# ATtiny828 register map
Vendor: Atmel; File version: 1.0
CPU: other r0p0, little endian, no MPU, no FPU, 4 interrupt priority bits
Registers are 8-bit, read-write, reset 0x0 unless marked. A register's access mark holds for its fields unless they carry their own. Offsets are from the block's base; [hi:lo] are bit positions; {n}, {i} and the like mark numbered series.

## LOCKBIT — Lockbits
Base 0x00000000
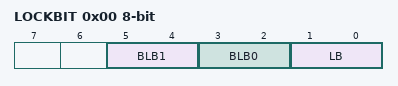
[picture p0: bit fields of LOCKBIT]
0x00 LOCKBIT
  [5:4] BLB1 — Boot Loader Protection Mode
    0=LPM_SPM_DISABLE (LPM and SPM prohibited in Boot Section); 1=LPM_DISABLE (LPM prohibited in Boot Section); 2=SPM_DISABLE (SPM prohibited in Boot Section); 3=NO_LOCK (No lock on SPM and LPM in Boot Section)
  [3:2] BLB0 — Boot Loader Protection Mode
    0=LPM_SPM_DISABLE (LPM and SPM prohibited in Application Section); 1=LPM_DISABLE (LPM prohibited in Application Section); 2=SPM_DISABLE (SPM prohibited in Application Section); 3=NO_LOCK (No lock on SPM and LPM in Application Section)
  [1:0] LB — Memory Lock
    0=PROG_VER_DISABLED (Further programming and verification disabled); 2=PROG_DISABLED (Further programming disabled); 3=NO_LOCK (No memory lock features enabled)

## PORTA — I/O Port
Base 0x00000020
0x00 PINA — Port A Input Pins
0x01 DDRA — Data Direction Register, Port A
0x02 PORTA — Port A Data Register
0x03 PUEA — Pull-up Enable Control Register

## PORTB — I/O Port
Base 0x00000024
0x00 PINB — Port B Input Pins
0x01 DDRB — Data Direction Register, Port B
0x02 PORTB — Port B Data Register
0x03 PUEB — Pull-up Enable Control Register

## PORTC — I/O Port
Base 0x00000028
0x00 PINC — Port C Input Pins
0x01 DDRC — Data Direction Register, Port C
0x02 PORTC — Port C Data Register
0x03 PUEC — Pull-up Enable Control Register
0x0C PHDE — Port High Drive Enable Register
  [2] PHDEC — Port C High Drive Enable

## PORTD — I/O Port
Base 0x0000002C
0x00 PIND — Port D Input Pins
0x01 DDRD — Data Direction Register, Port D
0x02 PORTD — Port D Data Register
0x03 PUED — Pull-up Enable Control Register

## SPI — Serial Peripheral Interface
Base 0x0000004C
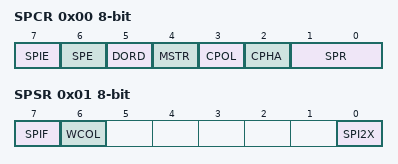
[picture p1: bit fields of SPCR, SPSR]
0x00 SPCR — SPI Control Register
  [7] SPIE — SPI Interrupt Enable
  [6] SPE — SPI Enable
  [5] DORD — Data Order
  [4] MSTR — Master/Slave Select
  [3] CPOL — Clock polarity
  [2] CPHA — Clock Phase
  [1:0] SPR — SPI Clock Rate Selects
    0=FOSC_4; 1=FOSC_16; 3=FOSC_128
0x01 SPSR — SPI Status Register
  [7] SPIF — SPI Interrupt Flag
  [6] WCOL — Write Collision Flag
  [0] SPI2X — Double SPI Speed Bit
0x02 SPDR — SPI Data Register

## TC0 — Timer/Counter, 8-bit
Base 0x00000035
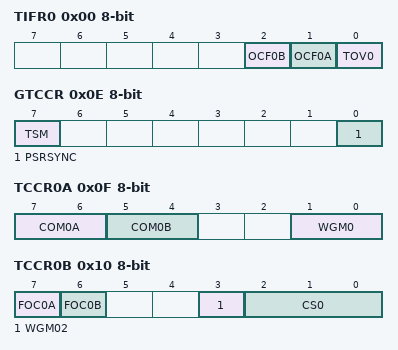
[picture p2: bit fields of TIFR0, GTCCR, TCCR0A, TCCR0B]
0x00 TIFR0 — Timer/Counter0 Interrupt Flag register
  [2] OCF0B — Timer/Counter0 Output Compare Flag 0B
  [1] OCF0A — Timer/Counter0 Output Compare Flag 0A
  [0] TOV0 — Timer/Counter0 Overflow Flag
0x0E GTCCR — General Timer/Counter Control Register
  [7] TSM — Timer/Counter Synchronization Mode
  [0] PSRSYNC — Prescaler Reset Timer/Counter1 and Timer/Counter0
0x0F TCCR0A — Timer/Counter Control Register A
  [7:6] COM0A — Compare Output Mode, Phase Correct PWM Mode
  [5:4] COM0B — Compare Output Mode, Fast PWm
  [1:0] WGM0 — Waveform Generation Mode
0x10 TCCR0B — Timer/Counter Control Register B
  [7] FOC0A — Force Output Compare A
  [6] FOC0B — Force Output Compare B
  [3] WGM02
  [2:0] CS0 — Clock Select
    0=NO_CLOCK_SOURCE_STOPPED; 1=RUNNING_NO_PRESCALING; 2=RUNNING_CLK_8; 3=RUNNING_CLK_64; 4=RUNNING_CLK_256; 5=RUNNING_CLK_1024; 6=RUNNING_EXTCLK_TN_FALLING_EDGE; 7=RUNNING_EXTCLK_TN_RISING_EDGE
0x11 TCNT0 — Timer/Counter0
0x12 OCR0A — Timer/Counter0 Output Compare Register
0x13 OCR0B — Timer/Counter0 Output Compare Register
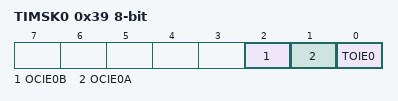
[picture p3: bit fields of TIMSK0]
0x39 TIMSK0 — Timer/Counter0 Interrupt Mask Register
  [2] OCIE0B — Timer/Counter0 Output Compare Match B Interrupt Enable
  [1] OCIE0A — Timer/Counter0 Output Compare Match A Interrupt Enable
  [0] TOIE0 — Timer/Counter0 Overflow Interrupt Enable

## TC1 — Timer/Counter, 16-bit
Base 0x00000036
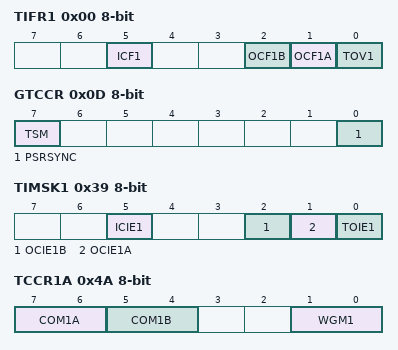
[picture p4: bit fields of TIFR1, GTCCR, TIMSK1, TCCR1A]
0x00 TIFR1 — Timer/Counter Interrupt Flag register
  [5] ICF1 — Input Capture Flag 1
  [2] OCF1B — Output Compare Flag 1B
  [1] OCF1A — Output Compare Flag 1A
  [0] TOV1 — Timer/Counter1 Overflow Flag
0x0D GTCCR — General Timer/Counter Control Register
  [7] TSM — Timer/Counter Synchronization Mode
  [0] PSRSYNC — Prescaler Reset Timer/Counter1 and Timer/Counter0
0x39 TIMSK1 — Timer/Counter Interrupt Mask Register
  [5] ICIE1 — Timer/Counter1 Input Capture Interrupt Enable
  [2] OCIE1B — Timer/Counter1 Output CompareB Match Interrupt Enable
  [1] OCIE1A — Timer/Counter1 Output CompareA Match Interrupt Enable
  [0] TOIE1 — Timer/Counter1 Overflow Interrupt Enable
0x4A TCCR1A — Timer/Counter1 Control Register A
  [7:6] COM1A — Compare Output Mode 1A, bits
  [5:4] COM1B — Compare Output Mode 1B, bits
  [1:0] WGM1 — Waveform Generation Mode
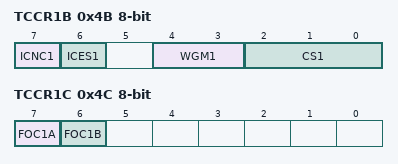
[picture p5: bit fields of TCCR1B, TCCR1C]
0x4B TCCR1B — Timer/Counter1 Control Register B
  [7] ICNC1 — Input Capture 1 Noise Canceler
  [6] ICES1 — Input Capture 1 Edge Select
  [4:3] WGM1 — Waveform Generation Mode
  [2:0] CS1 — Prescaler source of Timer/Counter 1
    0=NO_CLOCK_SOURCE_STOPPED; 1=RUNNING_NO_PRESCALING; 2=RUNNING_CLK_8; 3=RUNNING_CLK_64; 4=RUNNING_CLK_256; 5=RUNNING_CLK_1024; 6=RUNNING_EXTCLK_TN_FALLING_EDGE; 7=RUNNING_EXTCLK_TN_RISING_EDGE
0x4C TCCR1C — Timer/Counter1 Control Register C
  [7] FOC1A, [6] FOC1B
0x4E TCNT1 16-bit (reset mask 0xFF) — Timer/Counter1 Bytes
0x50 ICR1 16-bit (reset mask 0xFF) — Timer/Counter1 Input Capture Register Bytes
0x52 OCR1A 16-bit (reset mask 0xFF) — Timer/Counter1 Output Compare Register Bytes
0x54 OCR1B 16-bit (reset mask 0xFF) — Timer/Counter1 Output Compare Register Bytes

## TOCPM — Timer/Counter Output Compare Pin
Base 0x000000E2
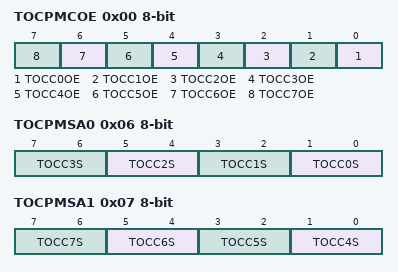
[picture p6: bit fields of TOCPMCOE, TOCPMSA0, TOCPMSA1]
0x00 TOCPMCOE — Timer Output Compare Pin Mux Channel Output Enable
  [n] TOCC{n}OE (n=0..7) — Timer Output Compare Channel {n} Output Enable
0x06 TOCPMSA0 — Timer Output Compare Pin Mux Selection 0
  [2n+1:2n] TOCC{n}S (n=0..3) — Timer Output Compare Channel {n} Selection Bits
0x07 TOCPMSA1 — Timer Output Compare Pin Mux Selection 1
  [2n-7:2n-8] TOCC{n}S (n=4..7) — Timer Output Compare Channel {n} Selection Bits

## TWI — Two Wire Serial Interface
Base 0x000000B8
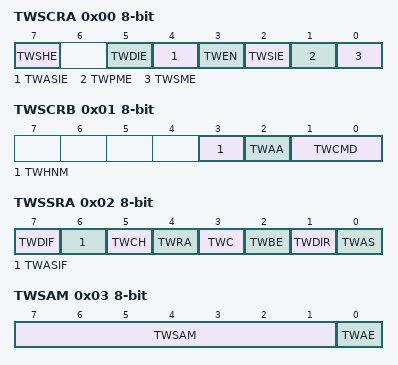
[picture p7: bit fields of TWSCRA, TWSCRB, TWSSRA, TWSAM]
0x00 TWSCRA — TWI Slave Control Register A
  [7] TWSHE — TWI SDA Hold Time Enable
  [5] TWDIE — TWI Data Interrupt Enable
  [4] TWASIE — TWI Address/Stop Interrupt Enable
  [3] TWEN — Two-Wire Interface Enable
  [2] TWSIE — TWI Stop Interrupt Enable
  [1] TWPME — TWI Promiscuous Mode Enable
  [0] TWSME — TWI Smart Mode Enable
0x01 TWSCRB — TWI Slave Control Register B
  [3] TWHNM — TWI High Noise Mode
  [2] TWAA — TWI Acknowledge Action
  [1:0] TWCMD
0x02 TWSSRA — TWI Slave Status Register A
  [7] TWDIF — TWI Data Interrupt Flag.
  [6] TWASIF — TWI Address/Stop Interrupt Flag
  [5] TWCH — TWI Clock Hold
  [4] TWRA — TWI Receive Acknowledge
  [3] TWC — TWI Collision
  [2] TWBE — TWI Bus Error
  [1] TWDIR — TWI Read/Write Direction
  [0] TWAS — TWI Address or Stop
0x03 TWSAM — TWI Slave Address Mask Register
  [7:1] TWSAM — TWI Address Mask Bits
  [0] TWAE — TWI Address Enable
0x04 TWSA — TWI Slave Address Register
0x05 TWSD — TWI Slave Data Register
  [7:0] TWSD — TWI slave data bit

## USART
Base 0x000000C0
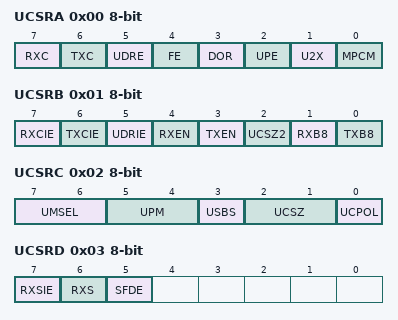
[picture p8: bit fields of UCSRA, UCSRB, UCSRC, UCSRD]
0x00 UCSRA — USART Control and Status Register A
  [7] RXC — USART Receive Complete
  [6] TXC — USART Transmitt Complete
  [5] UDRE — USART Data Register Empty
  [4] FE — Framing Error
  [3] DOR — Data overRun
  [2] UPE — Parity Error
  [1] U2X — Double the USART transmission speed
  [0] MPCM — Multi-processor Communication Mode
0x01 UCSRB — USART Control and Status Register B
  [7] RXCIE — RX Complete Interrupt Enable
  [6] TXCIE — TX Complete Interrupt Enable
  [5] UDRIE — USART Data register Empty Interrupt Enable
  [4] RXEN — Receiver Enable
  [3] TXEN — Transmitter Enable
  [2] UCSZ2 — Character Size
  [1] RXB8 — Receive Data Bit 8
  [0] TXB8 — Transmit Data Bit 8
0x02 UCSRC — USART Control and Status Register C
  [7:6] UMSEL — USART Mode Select
    0=ASYNCHRONOUS_OPERATION; 1=SYNCHRONOUS_OPERATION
  [5:4] UPM — Parity Mode Bits
    0=DISABLED; 2=ENABLED_EVEN_PARITY; 3=ENABLED_ODD_PARITY
  [3] USBS — Stop Bit Select
    0=1_BIT; 1=2_BIT
  [2:1] UCSZ — Character Size
  [0] UCPOL — Clock Polarity
0x03 UCSRD — USART Control and Status Register D
  [7] RXSIE — USART RX Start Interrupt Enable
  [6] RXS — USART RX Start Flag
  [5] SFDE — USART RX Start Frame Detection Enable
0x04 UBRR 16-bit (reset mask 0xFF) — USART Baud Rate Register Bytes
0x06 UDR — USART I/O Data Register

## WDT — Watchdog Timer
Base 0x00000060
0x00 WDTCSR — Watchdog Timer Control and Status Register
  [7] WDIF — Watchdog Timer Interrupt Flag
  [6] WDIE — Watchdog Timer Interrupt Enable
  [3] WDE — Watch Dog Enable
  [5:0] WDP — Watchdog Timer Prescaler Bits
    0=OSCILLATOR_CYCLES_512_16_MS; 1=OSCILLATOR_CYCLES_1K_32_MS; 2=OSCILLATOR_CYCLES_2K_64_MS; 3=OSCILLATOR_CYCLES_4K_0_125_S; 4=OSCILLATOR_CYCLES_8K_0_25_S; 5=OSCILLATOR_CYCLES_16K_0_5_S; 6=OSCILLATOR_CYCLES_32K_1_0_S; 7=OSCILLATOR_CYCLES_64K_2_0_S
